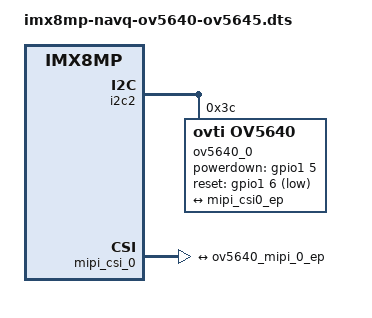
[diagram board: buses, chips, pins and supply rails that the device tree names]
// SPDX-License-Identifier: (GPL-2.0+ OR MIT)
/*
 * Copyright 2023 VoxelBotics
 * Copyright 2024 NXP
 */
#include "imx8mp-navq.dts"

&i2c2 {
	/delete-node/ov5645_mipi@3c;

	ov5640_0: ov5640_mipi@3c {
		compatible = "ovti,ov5640";
		reg = <0x3c>;
		pinctrl-names = "default";
		pinctrl-0 = <&pinctrl_csi0_pwn>, <&pinctrl_csi0_rst>, <&pinctrl_csi_mclk>;
		clocks = <&clk IMX8MP_CLK_IPP_DO_CLKO2>;
		clock-names = "xclk";
		assigned-clocks = <&clk IMX8MP_CLK_IPP_DO_CLKO1>;
		assigned-clock-parents = <&clk IMX8MP_CLK_24M>;
		assigned-clock-rates = <24000000>;
		csi_id = <0>;
		powerdown-gpios = <&gpio1 5 GPIO_ACTIVE_HIGH>;
		reset-gpios = <&gpio1 6 GPIO_ACTIVE_LOW>;
		mclk = <24000000>;
		mclk_source = <0>;
		status = "okay";

		port {
			ov5640_mipi_0_ep: endpoint {
				remote-endpoint = <&mipi_csi0_ep>;
				data-lanes = <1 2>;
				clock-lanes = <0>;
			};
		};
	};
};

&mipi_csi_0 {
	/delete-node/port@0;

	port@0 {
		reg = <0>;
		mipi_csi0_ep: endpoint {
			remote-endpoint = <&ov5640_mipi_0_ep>;
			data-lanes = <2>;
			csis-hs-settle = <13>;
			csis-clk-settle = <2>;
			csis-wclk;
		};
	};
};
